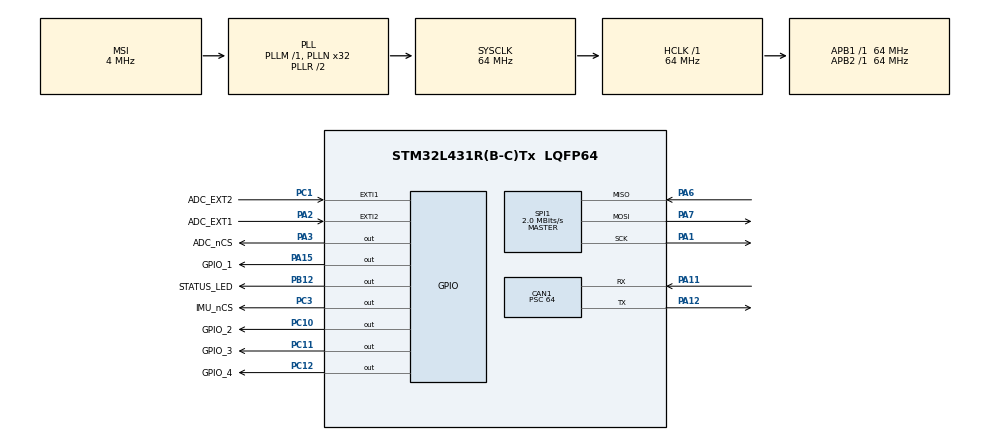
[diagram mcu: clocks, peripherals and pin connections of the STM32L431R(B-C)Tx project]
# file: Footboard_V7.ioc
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CAN1.BS1=CAN_BS1_4TQ
CAN1.BS2=CAN_BS2_4TQ
CAN1.CalculateBaudRate=111111
CAN1.CalculateTimeBit=9000
CAN1.CalculateTimeQuantum=1000.0
CAN1.Prescaler=64
Mcu.Family=STM32L4
Mcu.Name=STM32L431R(B-C)Tx
Mcu.Package=LQFP64
NVIC.CAN1_RX0_IRQn=true\:0\:0\:false\:false\:true\:true\:true\:true
NVIC.PriorityGroup=NVIC_PRIORITYGROUP_4
NVIC.TIM2_IRQn=true\:0\:0\:false\:false\:true\:true\:true\:true
PA1.Mode=Full_Duplex_Master
PA1.Signal=SPI1_SCK
PA11.Mode=CAN_Activate
PA11.Signal=CAN1_RX
PA12.Mode=CAN_Activate
PA12.Signal=CAN1_TX
PA13\ (JTMS-SWDIO).Mode=Serial_Wire
PA13\ (JTMS-SWDIO).Signal=SYS_JTMS-SWDIO
PA14\ (JTCK-SWCLK).Mode=Serial_Wire
PA14\ (JTCK-SWCLK).Signal=SYS_JTCK-SWCLK
PA15\ (JTDI).GPIO_Label=GPIO_1
PA15\ (JTDI).Signal=GPIO_Output
PA2.GPIO_Label=ADC_EXT1
PA2.Signal=GPXTI2
PA3.GPIO_Label=ADC_nCS
PA3.GPIO_Speed=GPIO_SPEED_FREQ_HIGH
PA3.PinState=GPIO_PIN_SET
PA3.Signal=GPIO_Output
PA6.Mode=Full_Duplex_Master
PA6.Signal=SPI1_MISO
PA7.Mode=Full_Duplex_Master
PA7.Signal=SPI1_MOSI
PB12.GPIO_Label=STATUS_LED
PB12.Signal=GPIO_Output
PC1.GPIO_Label=ADC_EXT2
PC1.Signal=GPXTI1
PC10.GPIO_Label=GPIO_2
PC10.Signal=GPIO_Output
PC11.GPIO_Label=GPIO_3
PC11.Signal=GPIO_Output
PC12.GPIO_Label=GPIO_4
PC12.Signal=GPIO_Output
PC3.GPIO_Label=IMU_nCS
PC3.GPIO_Speed=GPIO_SPEED_FREQ_HIGH
PC3.PinState=GPIO_PIN_SET
PC3.Signal=GPIO_Output
PH0-OSC_IN\ (PH0).Mode=HSE-External-Oscillator
PH0-OSC_IN\ (PH0).Signal=RCC_OSC_IN
PH1-OSC_OUT\ (PH1).Mode=HSE-External-Oscillator
PH1-OSC_OUT\ (PH1).Signal=RCC_OSC_OUT
ProjectManager.HeapSize=0x200
ProjectManager.StackSize=0x400
ProjectManager.TargetToolchain=STM32CubeIDE
RCC.ADCFreq_Value=16000000
RCC.AHBFreq_Value=64000000
RCC.APB1Freq_Value=64000000
RCC.APB1TimFreq_Value=64000000
RCC.APB2Freq_Value=64000000
RCC.APB2TimFreq_Value=64000000
RCC.CortexFreq_Value=64000000
RCC.HCLKFreq_Value=64000000
RCC.HSE_VALUE=8000000
RCC.HSI48_VALUE=48000000
RCC.HSI_VALUE=16000000
RCC.LSE_VALUE=32768
RCC.MSI_VALUE=4000000
RCC.PLLN=32
RCC.SYSCLKFreq_VALUE=64000000
RCC.SYSCLKSource=RCC_SYSCLKSOURCE_PLLCLK
RCC.VCOOutputFreq_Value=128000000
SPI1.BaudRatePrescaler=SPI_BAUDRATEPRESCALER_32
SPI1.CLKPhase=SPI_PHASE_1EDGE
SPI1.CLKPolarity=SPI_POLARITY_HIGH
SPI1.CalculateBaudRate=2.0 MBits/s
SPI1.DataSize=SPI_DATASIZE_8BIT
SPI1.Direction=SPI_DIRECTION_2LINES
SPI1.Mode=SPI_MODE_MASTER
SPI1.VirtualType=VM_MASTER
TIM2.CounterMode=TIM_COUNTERMODE_UP
TIM2.Period=64000
VP_TIM2_VS_ClockSourceINT.Mode=Internal
board=custom

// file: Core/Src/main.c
/* USER CODE BEGIN Header */
/**
  ******************************************************************************
  * @file           : main.c
  * @brief          : Main program body
  ******************************************************************************
  * @attention
  *
  * Copyright (c) 2023 STMicroelectronics.
  * All rights reserved.
  *
  * This software is licensed under terms that can be found in the LICENSE file
  * in the root directory of this software component.
  * If no LICENSE file comes with this software, it is provided AS-IS.
  *
  ******************************************************************************
  */
/* USER CODE END Header */
#include "main.h"

/* USER CODE BEGIN Includes */
#include "Footboard_main.h"

/* USER CODE END Includes */

CAN_HandleTypeDef hcan1;

SPI_HandleTypeDef hspi1;

TIM_HandleTypeDef htim2;

void SystemClock_Config(void);
static void MX_GPIO_Init(void);
static void MX_CAN1_Init(void);
static void MX_SPI1_Init(void);
static void MX_TIM2_Init(void);

int main(void)
{

  /* MCU Configuration--------------------------------------------------------*/

  /* Reset of all peripherals, Initializes the Flash interface and the Systick. */
  HAL_Init();

  /* Configure the system clock */
  SystemClock_Config();

  /* Initialize all configured peripherals */
  MX_GPIO_Init();
  MX_CAN1_Init();
  MX_SPI1_Init();
  MX_TIM2_Init();
  /* USER CODE BEGIN 2 */
  footboard_main();

  /* USER CODE END 2 */

  /* Infinite loop */
  while (1)
  {

  }
}

void SystemClock_Config(void)
{
  RCC_OscInitTypeDef RCC_OscInitStruct = {0};
  RCC_ClkInitTypeDef RCC_ClkInitStruct = {0};

  /** Configure the main internal regulator output voltage
  */
  if (HAL_PWREx_ControlVoltageScaling(PWR_REGULATOR_VOLTAGE_SCALE1) != HAL_OK)
  {
    Error_Handler();
  }

  /** Initializes the RCC Oscillators according to the specified parameters
  * in the RCC_OscInitTypeDef structure.
  */
  RCC_OscInitStruct.OscillatorType = RCC_OSCILLATORTYPE_MSI;
  RCC_OscInitStruct.MSIState = RCC_MSI_ON;
  RCC_OscInitStruct.MSICalibrationValue = 0;
  RCC_OscInitStruct.MSIClockRange = RCC_MSIRANGE_6;
  RCC_OscInitStruct.PLL.PLLState = RCC_PLL_ON;
  RCC_OscInitStruct.PLL.PLLSource = RCC_PLLSOURCE_MSI;
  RCC_OscInitStruct.PLL.PLLM = 1;
  RCC_OscInitStruct.PLL.PLLN = 32;
  RCC_OscInitStruct.PLL.PLLP = RCC_PLLP_DIV7;
  RCC_OscInitStruct.PLL.PLLQ = RCC_PLLQ_DIV2;
  RCC_OscInitStruct.PLL.PLLR = RCC_PLLR_DIV2;
  if (HAL_RCC_OscConfig(&RCC_OscInitStruct) != HAL_OK)
  {
    Error_Handler();
  }

  /** Initializes the CPU, AHB and APB buses clocks
  */
  RCC_ClkInitStruct.ClockType = RCC_CLOCKTYPE_HCLK|RCC_CLOCKTYPE_SYSCLK
                              |RCC_CLOCKTYPE_PCLK1|RCC_CLOCKTYPE_PCLK2;
  RCC_ClkInitStruct.SYSCLKSource = RCC_SYSCLKSOURCE_PLLCLK;
  RCC_ClkInitStruct.AHBCLKDivider = RCC_SYSCLK_DIV1;
  RCC_ClkInitStruct.APB1CLKDivider = RCC_HCLK_DIV1;
  RCC_ClkInitStruct.APB2CLKDivider = RCC_HCLK_DIV1;

  if (HAL_RCC_ClockConfig(&RCC_ClkInitStruct, FLASH_LATENCY_3) != HAL_OK)
  {
    Error_Handler();
  }
}

static void MX_CAN1_Init(void)
{

  hcan1.Instance = CAN1;
  hcan1.Init.Prescaler = 64;
  hcan1.Init.Mode = CAN_MODE_NORMAL;
  hcan1.Init.SyncJumpWidth = CAN_SJW_1TQ;
  hcan1.Init.TimeSeg1 = CAN_BS1_4TQ;
  hcan1.Init.TimeSeg2 = CAN_BS2_4TQ;
  hcan1.Init.TimeTriggeredMode = DISABLE;
  hcan1.Init.AutoBusOff = DISABLE;
  hcan1.Init.AutoWakeUp = DISABLE;
  hcan1.Init.AutoRetransmission = DISABLE;
  hcan1.Init.ReceiveFifoLocked = DISABLE;
  hcan1.Init.TransmitFifoPriority = DISABLE;
  if (HAL_CAN_Init(&hcan1) != HAL_OK)
  {
    Error_Handler();
  }

}

static void MX_SPI1_Init(void)
{

  /* SPI1 parameter configuration*/
  hspi1.Instance = SPI1;
  hspi1.Init.Mode = SPI_MODE_MASTER;
  hspi1.Init.Direction = SPI_DIRECTION_2LINES;
  hspi1.Init.DataSize = SPI_DATASIZE_8BIT;
  hspi1.Init.CLKPolarity = SPI_POLARITY_HIGH;
  hspi1.Init.CLKPhase = SPI_PHASE_1EDGE;
  hspi1.Init.NSS = SPI_NSS_SOFT;
  hspi1.Init.BaudRatePrescaler = SPI_BAUDRATEPRESCALER_32;
  hspi1.Init.FirstBit = SPI_FIRSTBIT_MSB;
  hspi1.Init.TIMode = SPI_TIMODE_DISABLE;
  hspi1.Init.CRCCalculation = SPI_CRCCALCULATION_DISABLE;
  hspi1.Init.CRCPolynomial = 7;
  hspi1.Init.CRCLength = SPI_CRC_LENGTH_DATASIZE;
  hspi1.Init.NSSPMode = SPI_NSS_PULSE_ENABLE;
  if (HAL_SPI_Init(&hspi1) != HAL_OK)
  {
    Error_Handler();
  }

}

static void MX_TIM2_Init(void)
{

  TIM_ClockConfigTypeDef sClockSourceConfig = {0};
  TIM_MasterConfigTypeDef sMasterConfig = {0};

  htim2.Instance = TIM2;
  htim2.Init.Prescaler = 0;
  htim2.Init.CounterMode = TIM_COUNTERMODE_UP;
  htim2.Init.Period = 64000;
  htim2.Init.ClockDivision = TIM_CLOCKDIVISION_DIV1;
  htim2.Init.AutoReloadPreload = TIM_AUTORELOAD_PRELOAD_DISABLE;
  if (HAL_TIM_Base_Init(&htim2) != HAL_OK)
  {
    Error_Handler();
  }
  sClockSourceConfig.ClockSource = TIM_CLOCKSOURCE_INTERNAL;
  if (HAL_TIM_ConfigClockSource(&htim2, &sClockSourceConfig) != HAL_OK)
  {
    Error_Handler();
  }
  sMasterConfig.MasterOutputTrigger = TIM_TRGO_RESET;
  sMasterConfig.MasterSlaveMode = TIM_MASTERSLAVEMODE_DISABLE;
  if (HAL_TIMEx_MasterConfigSynchronization(&htim2, &sMasterConfig) != HAL_OK)
  {
    Error_Handler();
  }

}

static void MX_GPIO_Init(void)
{
  GPIO_InitTypeDef GPIO_InitStruct = {0};

  /* GPIO Ports Clock Enable */
  __HAL_RCC_GPIOH_CLK_ENABLE();
  __HAL_RCC_GPIOC_CLK_ENABLE();
  __HAL_RCC_GPIOA_CLK_ENABLE();
  __HAL_RCC_GPIOB_CLK_ENABLE();

  /*Configure GPIO pin Output Level */
  HAL_GPIO_WritePin(IMU_nCS_GPIO_Port, IMU_nCS_Pin, GPIO_PIN_SET);

  /*Configure GPIO pin Output Level */
  HAL_GPIO_WritePin(ADC_nCS_GPIO_Port, ADC_nCS_Pin, GPIO_PIN_SET);

  /*Configure GPIO pin Output Level */
  HAL_GPIO_WritePin(STATUS_LED_GPIO_Port, STATUS_LED_Pin, GPIO_PIN_RESET);

  /*Configure GPIO pin Output Level */
  HAL_GPIO_WritePin(GPIO_1_GPIO_Port, GPIO_1_Pin, GPIO_PIN_RESET);

  /*Configure GPIO pin Output Level */
  HAL_GPIO_WritePin(GPIOC, GPIO_2_Pin|GPIO_3_Pin|GPIO_4_Pin, GPIO_PIN_RESET);

  /*Configure GPIO pin : ADC_EXT2_Pin */
  GPIO_InitStruct.Pin = ADC_EXT2_Pin;
  GPIO_InitStruct.Mode = GPIO_MODE_IT_RISING;
  GPIO_InitStruct.Pull = GPIO_NOPULL;
  HAL_GPIO_Init(ADC_EXT2_GPIO_Port, &GPIO_InitStruct);

  /*Configure GPIO pin : IMU_nCS_Pin */
  GPIO_InitStruct.Pin = IMU_nCS_Pin;
  GPIO_InitStruct.Mode = GPIO_MODE_OUTPUT_PP;
  GPIO_InitStruct.Pull = GPIO_NOPULL;
  GPIO_InitStruct.Speed = GPIO_SPEED_FREQ_HIGH;
  HAL_GPIO_Init(IMU_nCS_GPIO_Port, &GPIO_InitStruct);

  /*Configure GPIO pin : ADC_EXT1_Pin */
  GPIO_InitStruct.Pin = ADC_EXT1_Pin;
  GPIO_InitStruct.Mode = GPIO_MODE_IT_RISING;
  GPIO_InitStruct.Pull = GPIO_NOPULL;
  HAL_GPIO_Init(ADC_EXT1_GPIO_Port, &GPIO_InitStruct);

  /*Configure GPIO pin : ADC_nCS_Pin */
  GPIO_InitStruct.Pin = ADC_nCS_Pin;
  GPIO_InitStruct.Mode = GPIO_MODE_OUTPUT_PP;
  GPIO_InitStruct.Pull = GPIO_NOPULL;
  GPIO_InitStruct.Speed = GPIO_SPEED_FREQ_HIGH;
  HAL_GPIO_Init(ADC_nCS_GPIO_Port, &GPIO_InitStruct);

  /*Configure GPIO pin : STATUS_LED_Pin */
  GPIO_InitStruct.Pin = STATUS_LED_Pin;
  GPIO_InitStruct.Mode = GPIO_MODE_OUTPUT_PP;
  GPIO_InitStruct.Pull = GPIO_NOPULL;
  GPIO_InitStruct.Speed = GPIO_SPEED_FREQ_LOW;
  HAL_GPIO_Init(STATUS_LED_GPIO_Port, &GPIO_InitStruct);

  /*Configure GPIO pin : GPIO_1_Pin */
  GPIO_InitStruct.Pin = GPIO_1_Pin;
  GPIO_InitStruct.Mode = GPIO_MODE_OUTPUT_PP;
  GPIO_InitStruct.Pull = GPIO_NOPULL;
  GPIO_InitStruct.Speed = GPIO_SPEED_FREQ_LOW;
  HAL_GPIO_Init(GPIO_1_GPIO_Port, &GPIO_InitStruct);

  /*Configure GPIO pins : GPIO_2_Pin GPIO_3_Pin GPIO_4_Pin */
  GPIO_InitStruct.Pin = GPIO_2_Pin|GPIO_3_Pin|GPIO_4_Pin;
  GPIO_InitStruct.Mode = GPIO_MODE_OUTPUT_PP;
  GPIO_InitStruct.Pull = GPIO_NOPULL;
  GPIO_InitStruct.Speed = GPIO_SPEED_FREQ_LOW;
  HAL_GPIO_Init(GPIOC, &GPIO_InitStruct);

}

void Error_Handler(void)
{
  __disable_irq();
  while (1)
  {
  }
}
